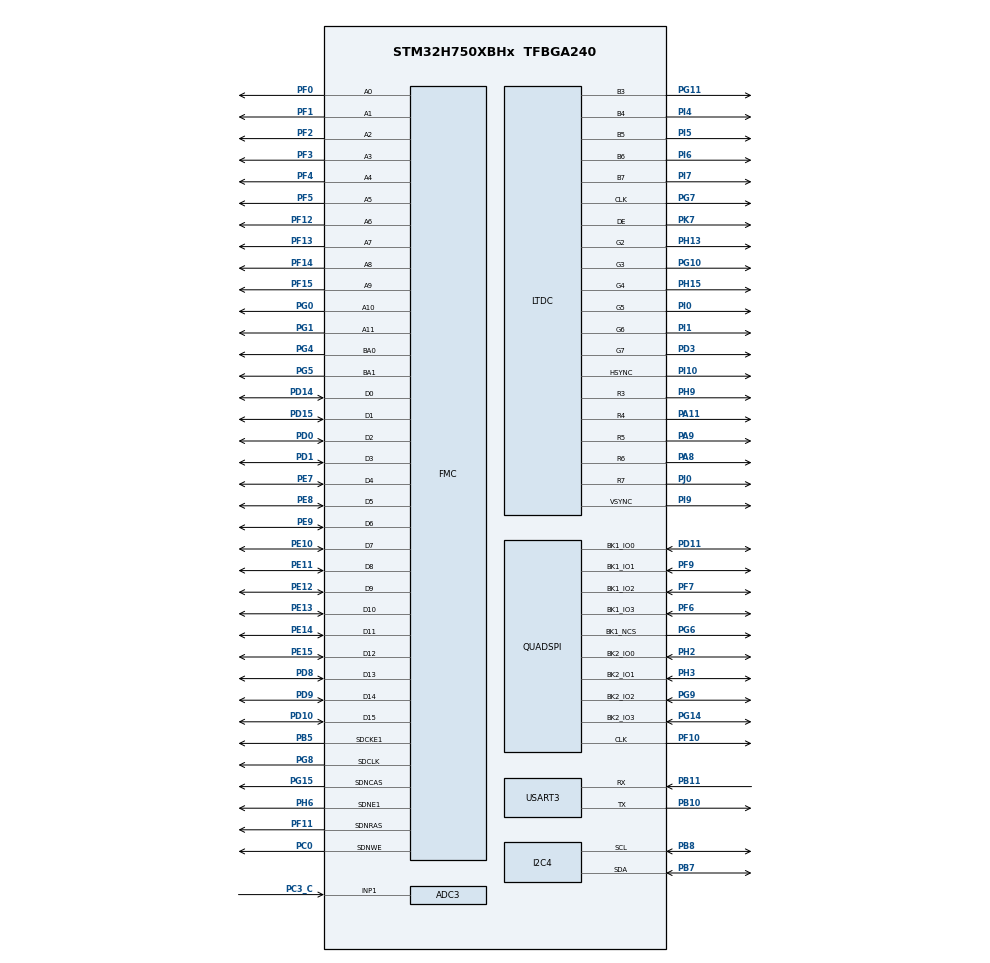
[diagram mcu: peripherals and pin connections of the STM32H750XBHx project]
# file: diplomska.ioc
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ADC3.Channel-3\#ChannelRegularConversion=ADC_CHANNEL_1
ADC3.ExternalTrigConv=ADC_EXTERNALTRIG_T2_CC2
ADC3.NbrOfConversionFlag=1
ADC3.OffsetNumber-3\#ChannelRegularConversion=ADC_OFFSET_NONE
ADC3.OffsetSignedSaturation-3\#ChannelRegularConversion=DISABLE
ADC3.Rank-3\#ChannelRegularConversion=1
ADC3.SamplingTime-3\#ChannelRegularConversion=ADC_SAMPLETIME_1CYCLE_5
CORTEX_M7.CPU_DCache=Enabled
CORTEX_M7.CPU_ICache=Enabled
CORTEX_M7.default_mode_Activation=1
DMA2D.ColorMode=DMA2D_OUTPUT_RGB565
FMC.CASLatency2=FMC_SDRAM_CAS_LATENCY_2
FMC.ExitSelfRefreshDelay2=7
FMC.LoadToActiveDelay2=2
FMC.RCDDelay2=2
FMC.RPDelay2=2
FMC.RowCycleDelay2=7
FMC.SDClockPeriod2=FMC_SDRAM_CLOCK_PERIOD_2
FMC.SelfRefreshTime2=4
FMC.WriteRecoveryTime2=3
FREERTOS.Tasks01=inferenceTask,24,3840,StartInferenceTask,Default,NULL,Dynamic,NULL,NULL;uiTask,8,2048,StartUiTask,Default,NULL,Dynamic,NULL,NULL
FREERTOS.configTOTAL_HEAP_SIZE=98304
FREERTOS.configUSE_NEWLIB_REENTRANT=1
I2C4.Timing=0x307075B1
LTDC.ActiveH=272
LTDC.ActiveW=480
Mcu.Family=STM32H7
Mcu.Name=STM32H750XBHx
Mcu.Package=TFBGA240
NVIC.DMA2D_IRQn=true\:5\:0\:false\:false\:true\:true\:true\:true\:true
NVIC.I2C4_ER_IRQn=true\:5\:0\:false\:false\:true\:true\:true\:true\:true
NVIC.I2C4_EV_IRQn=true\:5\:0\:false\:false\:true\:true\:true\:true\:true
NVIC.PriorityGroup=NVIC_PRIORITYGROUP_4
NVIC.TIM1_UP_IRQn=true\:15\:0\:false\:false\:true\:false\:false\:true\:true
NVIC.TimeBase=TIM1_UP_IRQn
NVIC.TimeBaseIP=TIM1
NVIC.USART3_IRQn=true\:5\:0\:false\:false\:true\:true\:true\:true\:true
PA11.Mode=RGB565
PA11.Signal=LTDC_R4
PA8.Mode=RGB565
PA8.Signal=LTDC_R6
PA9.Mode=RGB565
PA9.Signal=LTDC_R5
PB10.Mode=Asynchronous
PB10.Signal=USART3_TX
PB11.Mode=Asynchronous
PB11.Signal=USART3_RX
PB5.Mode=SdramChipSelect2_2
PB5.Signal=FMC_SDCKE1
PB7.Mode=I2C
PB7.Signal=I2C4_SDA
PB8.Mode=I2C
PB8.Signal=I2C4_SCL
PC0.Signal=FMC_SDNWE
PC3_C.Mode=IN1-Single-Ended
PC3_C.Signal=ADC3_INP1
PD0.Signal=FMC_D2_DA2
PD1.Signal=FMC_D3_DA3
PD10.Signal=FMC_D15_DA15
PD11.Mode=Dual_Bank
PD11.Signal=QUADSPI_BK1_IO0
PD14.Signal=FMC_D0_DA0
PD15.Signal=FMC_D1_DA1
PD3.Mode=RGB565
PD3.Signal=LTDC_G7
PD8.Signal=FMC_D13_DA13
PD9.Signal=FMC_D14_DA14
PE10.Signal=FMC_D7_DA7
PE11.Signal=FMC_D8_DA8
PE12.Signal=FMC_D9_DA9
PE13.Signal=FMC_D10_DA10
PE14.Signal=FMC_D11_DA11
PE15.Signal=FMC_D12_DA12
PE7.Signal=FMC_D4_DA4
PE8.Signal=FMC_D5_DA5
PE9.Signal=FMC_D6_DA6
PF0.Signal=FMC_A0
PF1.Signal=FMC_A1
PF10.Mode=Dual_Bank
PF10.Signal=QUADSPI_CLK
PF11.Signal=FMC_SDNRAS
PF12.Signal=FMC_A6
PF13.Signal=FMC_A7
PF14.Signal=FMC_A8
PF15.Signal=FMC_A9
PF2.Signal=FMC_A2
PF3.Signal=FMC_A3
PF4.Signal=FMC_A4
PF5.Signal=FMC_A5
PF6.Mode=Dual_Bank
PF6.Signal=QUADSPI_BK1_IO3
PF7.Mode=Dual_Bank
PF7.Signal=QUADSPI_BK1_IO2
PF9.Mode=Dual_Bank
PF9.Signal=QUADSPI_BK1_IO1
PG0.Signal=FMC_A10
PG1.Signal=FMC_A11
PG10.Mode=RGB565
PG10.Signal=LTDC_G3
PG11.Mode=RGB565
PG11.Signal=LTDC_B3
PG14.Mode=Dual_Bank
PG14.Signal=QUADSPI_BK2_IO3
PG15.Signal=FMC_SDNCAS
PG4.Signal=FMC_A14_BA0
PG5.Signal=FMC_A15_BA1
PG6.Mode=Enable Chip Select 1 for both banks
PG6.Signal=QUADSPI_BK1_NCS
PG7.Mode=RGB565
PG7.Signal=LTDC_CLK
PG8.Signal=FMC_SDCLK
PG9.Mode=Dual_Bank
PG9.Signal=QUADSPI_BK2_IO2
PH0-OSC_IN\ (PH0).Mode=HSE-External-Clock-Source
PH0-OSC_IN\ (PH0).Signal=RCC_OSC_IN
PH13.Mode=RGB565
PH13.Signal=LTDC_G2
PH15.Mode=RGB565
PH15.Signal=LTDC_G4
PH2.Mode=Dual_Bank
PH2.Signal=QUADSPI_BK2_IO0
PH3.Mode=Dual_Bank
PH3.Signal=QUADSPI_BK2_IO1
PH6.Mode=SdramChipSelect2_2
PH6.Signal=FMC_SDNE1
PH9.Mode=RGB565
PH9.Signal=LTDC_R3
PI0.Mode=RGB565
PI0.Signal=LTDC_G5
PI1.Mode=RGB565
PI1.Signal=LTDC_G6
PI10.Mode=RGB565
PI10.Signal=LTDC_HSYNC
PI4.Mode=RGB565
PI4.Signal=LTDC_B4
PI5.Mode=RGB565
PI5.Signal=LTDC_B5
PI6.Mode=RGB565
PI6.Signal=LTDC_B6
PI7.Mode=RGB565
PI7.Signal=LTDC_B7
PI9.Mode=RGB565
PI9.Signal=LTDC_VSYNC
PJ0.Mode=RGB565
PJ0.Signal=LTDC_R7
PK7.Mode=RGB565
PK7.Signal=LTDC_DE
ProjectManager.HeapSize=0x800
ProjectManager.StackSize=0x800
ProjectManager.TargetToolchain=STM32CubeIDE
QUADSPI.ChipSelectHighTime=QSPI_CS_HIGH_TIME_6_CYCLE
QUADSPI.ClockPrescaler=0
QUADSPI.FifoThreshold=4
QUADSPI.FlashSize=26
QUADSPI.SampleShifting=QSPI_SAMPLE_SHIFTING_HALFCYCLE
RCC.ADCFreq_Value=50000000
RCC.APB1CLKDivider=RCC_HCLK_DIV4
RCC.APB1Freq_Value=120000000
RCC.APB2CLKDivider=RCC_HCLK_DIV2
RCC.APB2Freq_Value=120000000
RCC.APB3Freq_Value=120000000
RCC.APB4Freq_Value=120000000
RCC.CortexFreq_Value=480000000
RCC.D1PPRE=RCC_APB3_DIV2
RCC.D2PPRE1=RCC_APB1_DIV2
RCC.D2PPRE2=RCC_APB2_DIV2
RCC.D3PPRE=RCC_APB4_DIV2
RCC.DIVM1=5
RCC.DIVM2=5
RCC.DIVM3=5
RCC.DIVN1=192
RCC.DIVN2=80
RCC.DIVN3=32
RCC.DIVP2=8
RCC.DIVQ1=4
RCC.DIVQ2=4
RCC.DIVR2=4
RCC.DIVR3=16
RCC.FLatency=FLASH_LATENCY_4
RCC.FMCCLockSelection=RCC_FMCCLKSOURCE_PLL2
RCC.HCLKFreq_Value=240000000
RCC.HPRE=RCC_HCLK_DIV2
RCC.HSE_VALUE=25000000
RCC.PLL2FRACN=0
RCC.PLL3FRACN=0
RCC.PLLFRACN=0
RCC.PLLM=25
RCC.PLLMUL=RCC_PLL_MUL9
RCC.PLLN=432
RCC.PLLQ=9
RCC.PLLSourceVirtual=RCC_PLLSOURCE_HSE
RCC.PRESCALERUSB=RCC_USBCLKSOURCE_PLL_DIV1_5
RCC.PWR_Regulator_Voltage_Scale=PWR_REGULATOR_VOLTAGE_SCALE0
RCC.QSPICLockSelection=RCC_QSPICLKSOURCE_PLL2
RCC.SYSCLKFreq_VALUE=480000000
RCC.SYSCLKSource=RCC_SYSCLKSOURCE_PLLCLK
RCC.SYSCLKSourceVirtual=RCC_SYSCLKSOURCE_PLLCLK
RCC.USBFreq_Value=240000000
SH.FMC_A0.0=FMC_A0,12b-sda2
SH.FMC_A1.0=FMC_A1,12b-sda2
SH.FMC_A10.0=FMC_A10,12b-sda2
SH.FMC_A11.0=FMC_A11,12b-sda2
SH.FMC_A14_BA0.0=FMC_BA0,FourSdramBanks2
SH.FMC_A15_BA1.0=FMC_BA1,FourSdramBanks2
SH.FMC_A2.0=FMC_A2,12b-sda2
SH.FMC_A3.0=FMC_A3,12b-sda2
SH.FMC_A4.0=FMC_A4,12b-sda2
SH.FMC_A5.0=FMC_A5,12b-sda2
SH.FMC_A6.0=FMC_A6,12b-sda2
SH.FMC_A7.0=FMC_A7,12b-sda2
SH.FMC_A8.0=FMC_A8,12b-sda2
SH.FMC_A9.0=FMC_A9,12b-sda2
SH.FMC_D0_DA0.0=FMC_D0,sd-16b-d2
SH.FMC_D10_DA10.0=FMC_D10,sd-16b-d2
SH.FMC_D11_DA11.0=FMC_D11,sd-16b-d2
SH.FMC_D12_DA12.0=FMC_D12,sd-16b-d2
SH.FMC_D13_DA13.0=FMC_D13,sd-16b-d2
SH.FMC_D14_DA14.0=FMC_D14,sd-16b-d2
SH.FMC_D15_DA15.0=FMC_D15,sd-16b-d2
SH.FMC_D1_DA1.0=FMC_D1,sd-16b-d2
SH.FMC_D2_DA2.0=FMC_D2,sd-16b-d2
SH.FMC_D3_DA3.0=FMC_D3,sd-16b-d2
SH.FMC_D4_DA4.0=FMC_D4,sd-16b-d2
SH.FMC_D5_DA5.0=FMC_D5,sd-16b-d2
SH.FMC_D6_DA6.0=FMC_D6,sd-16b-d2
SH.FMC_D7_DA7.0=FMC_D7,sd-16b-d2
SH.FMC_D8_DA8.0=FMC_D8,sd-16b-d2
SH.FMC_D9_DA9.0=FMC_D9,sd-16b-d2
SH.FMC_SDCLK.0=FMC_SDCLK,12b-sda2
SH.FMC_SDNCAS.0=FMC_SDNCAS,12b-sda2
SH.FMC_SDNRAS.0=FMC_SDNRAS,12b-sda2
SH.FMC_SDNWE.0=FMC_SDNWE,12b-sda2
STMicroelectronics.X-CUBE-AI.9.0.0.ActivationBufferSizeList=5348
STMicroelectronics.X-CUBE-AI.9.0.0.ActivationBuffers=pool0
STMicroelectronics.X-CUBE-AI.9.0.0.ActivationNames=pool0
STMicroelectronics.X-CUBE-AI.9.0.0.ActivationSizes=AI_STROKES_DATA_ACTIVATION_1_SIZE
STMicroelectronics.X-CUBE-AI.9.0.0.ApplicationCcDeviceJjApplication=ApplicationTemplate
STMicroelectronics.X-CUBE-AI.9.0.0.HeapSize=0x800
STMicroelectronics.X-CUBE-AI.9.0.0.InternalRamActivationBufferMaxSize=AI_STROKES_DATA_ACTIVATIONS_SIZE
STMicroelectronics.X-CUBE-AI.9.0.0.LatestDirectoryUsed-7118fc1bdd9c5cdb83d505c0c15efabca41f38ba9d3231cf816e6ee5fc640e7f=C\:\\Users\\cam\\Documents\\007_peskovnik\\15_delovna_mapa\\MODEL\\strokes
STMicroelectronics.X-CUBE-AI.9.0.0.LatestDirectoryUsed-9d803ac0ba18cdfca45ca4e4886879cd2de36854d513869ccf0e9e250b180b08=C\:\\Users\\cam\\Documents\\006_DIP\\003_poskus2\\jupyter
STMicroelectronics.X-CUBE-AI.9.0.0.MaximumNumberOfInputLayer=1
STMicroelectronics.X-CUBE-AI.9.0.0.MaximumNumberOfOutputLayer=1
STMicroelectronics.X-CUBE-AI.9.0.0.MaximumSizeOfInputLayer=1
STMicroelectronics.X-CUBE-AI.9.0.0.MaximumSizeOfOutputLayer=1
STMicroelectronics.X-CUBE-AI.9.0.0.ModelActualCompression-7118fc1bdd9c5cdb83d505c0c15efabca41f38ba9d3231cf816e6ee5fc640e7f=0.0
STMicroelectronics.X-CUBE-AI.9.0.0.ModelActualCompression-9d803ac0ba18cdfca45ca4e4886879cd2de36854d513869ccf0e9e250b180b08=0.0
STMicroelectronics.X-CUBE-AI.9.0.0.ModelCompression-7118fc1bdd9c5cdb83d505c0c15efabca41f38ba9d3231cf816e6ee5fc640e7f=None
STMicroelectronics.X-CUBE-AI.9.0.0.ModelCompression-9d803ac0ba18cdfca45ca4e4886879cd2de36854d513869ccf0e9e250b180b08=None
STMicroelectronics.X-CUBE-AI.9.0.0.ModelFlashOccupation-7118fc1bdd9c5cdb83d505c0c15efabca41f38ba9d3231cf816e6ee5fc640e7f=92028
STMicroelectronics.X-CUBE-AI.9.0.0.ModelFlashOccupation-9d803ac0ba18cdfca45ca4e4886879cd2de36854d513869ccf0e9e250b180b08=16104
STMicroelectronics.X-CUBE-AI.9.0.0.ModelHashList=7118fc1bdd9c5cdb83d505c0c15efabca41f38ba9d3231cf816e6ee5fc640e7f
STMicroelectronics.X-CUBE-AI.9.0.0.ModelKind-7118fc1bdd9c5cdb83d505c0c15efabca41f38ba9d3231cf816e6ee5fc640e7f=TFLITE
STMicroelectronics.X-CUBE-AI.9.0.0.ModelKind-9d803ac0ba18cdfca45ca4e4886879cd2de36854d513869ccf0e9e250b180b08=TFLITE
STMicroelectronics.X-CUBE-AI.9.0.0.ModelMacc-7118fc1bdd9c5cdb83d505c0c15efabca41f38ba9d3231cf816e6ee5fc640e7f=69872
STMicroelectronics.X-CUBE-AI.9.0.0.ModelMacc-9d803ac0ba18cdfca45ca4e4886879cd2de36854d513869ccf0e9e250b180b08=305096
STMicroelectronics.X-CUBE-AI.9.0.0.ModelName-7118fc1bdd9c5cdb83d505c0c15efabca41f38ba9d3231cf816e6ee5fc640e7f=strokes
STMicroelectronics.X-CUBE-AI.9.0.0.ModelName-9d803ac0ba18cdfca45ca4e4886879cd2de36854d513869ccf0e9e250b180b08=bitmaps
STMicroelectronics.X-CUBE-AI.9.0.0.ModelNameList=strokes
STMicroelectronics.X-CUBE-AI.9.0.0.ModelRamOccupation-7118fc1bdd9c5cdb83d505c0c15efabca41f38ba9d3231cf816e6ee5fc640e7f=5348
STMicroelectronics.X-CUBE-AI.9.0.0.ModelRamOccupation-9d803ac0ba18cdfca45ca4e4886879cd2de36854d513869ccf0e9e250b180b08=10480
STMicroelectronics.X-CUBE-AI.9.0.0.ModelStructureFile-7118fc1bdd9c5cdb83d505c0c15efabca41f38ba9d3231cf816e6ee5fc640e7f=C\:\\Users\\cam\\Documents\\007_peskovnik\\15_delovna_mapa\\MODEL\\strokes\\strokes.tflite
STMicroelectronics.X-CUBE-AI.9.0.0.ModelStructureFile-9d803ac0ba18cdfca45ca4e4886879cd2de36854d513869ccf0e9e250b180b08=C\:\\Users\\cam\\Documents\\006_DIP\\003_poskus2\\jupyter\\small-emnist.tflite
STMicroelectronics.X-CUBE-AI.9.0.0.ModelType-7118fc1bdd9c5cdb83d505c0c15efabca41f38ba9d3231cf816e6ee5fc640e7f=STM32Cube.AI MCU runtime
STMicroelectronics.X-CUBE-AI.9.0.0.ModelType-9d803ac0ba18cdfca45ca4e4886879cd2de36854d513869ccf0e9e250b180b08=STM32Cube.AI MCU runtime
STMicroelectronics.X-CUBE-AI.9.0.0.ReadyForCodeGeneration=true
STMicroelectronics.X-CUBE-AI.9.0.0.StackSize=0x800
STMicroelectronics.X-CUBE-AI.9.0.0.WorkingBufferStartAddrList=0xFFFFFFFF
STMicroelectronics.X-CUBE-AI.9.0.0.XAaCUBEAaAICcArtificialOoIntelligenceJjCore=true
STMicroelectronics.X-CUBE-AI.9.0.0.copyWeightToRam-7118fc1bdd9c5cdb83d505c0c15efabca41f38ba9d3231cf816e6ee5fc640e7f=false
STMicroelectronics.X-CUBE-AI.9.0.0.copyWeightToRam-9d803ac0ba18cdfca45ca4e4886879cd2de36854d513869ccf0e9e250b180b08=false
STMicroelectronics.X-CUBE-AI.9.0.0.customLayerConfigEnabled-7118fc1bdd9c5cdb83d505c0c15efabca41f38ba9d3231cf816e6ee5fc640e7f=false
STMicroelectronics.X-CUBE-AI.9.0.0.customLayerConfigEnabled-9d803ac0ba18cdfca45ca4e4886879cd2de36854d513869ccf0e9e250b180b08=false
STMicroelectronics.X-CUBE-AI.9.0.0.extFlashDriver-9d803ac0ba18cdfca45ca4e4886879cd2de36854d513869ccf0e9e250b180b08=Custom
STMicroelectronics.X-CUBE-AI.9.0.0.extFlashStartAddr-9d803ac0ba18cdfca45ca4e4886879cd2de36854d513869ccf0e9e250b180b08=0x90100000
STMicroelectronics.X-CUBE-AI.9.0.0.noOnnxIoTranspose-7118fc1bdd9c5cdb83d505c0c15efabca41f38ba9d3231cf816e6ee5fc640e7f=false
STMicroelectronics.X-CUBE-AI.9.0.0.noOnnxIoTranspose-9d803ac0ba18cdfca45ca4e4886879cd2de36854d513869ccf0e9e250b180b08=false
STMicroelectronics.X-CUBE-AI.9.0.0.useExternalFlash-9d803ac0ba18cdfca45ca4e4886879cd2de36854d513869ccf0e9e250b180b08=true
STMicroelectronics.X-CUBE-AI.9.0.0.useInputAllocation-7118fc1bdd9c5cdb83d505c0c15efabca41f38ba9d3231cf816e6ee5fc640e7f=true
STMicroelectronics.X-CUBE-AI.9.0.0.useInputAllocation-9d803ac0ba18cdfca45ca4e4886879cd2de36854d513869ccf0e9e250b180b08=true
STMicroelectronics.X-CUBE-AI.9.0.0.useOutputAllocation-7118fc1bdd9c5cdb83d505c0c15efabca41f38ba9d3231cf816e6ee5fc640e7f=true
STMicroelectronics.X-CUBE-AI.9.0.0.useOutputAllocation-9d803ac0ba18cdfca45ca4e4886879cd2de36854d513869ccf0e9e250b180b08=true
TIM2.Period=999
TIM2.Prescaler=23999
TIM2.TIM_MasterOutputTrigger=TIM_TRGO_UPDATE
USART3.VirtualMode-Asynchronous=VM_ASYNC
VP_DMA2D_VS_DMA2D.Mode=DMA2D_Activate
VP_FREERTOS_VS_CMSIS_V2.Mode=CMSIS_V2
VP_MEMORYMAP_VS_MEMORYMAP.Mode=CurAppReg
VP_STMicroelectronics.X-CUBE-AI_VS_ArtificialOoIntelligenceJjXAaCUBEAaAI_9.0.0.Mode=ArtificialOoIntelligenceJjXAaCUBEAaAI
VP_STMicroelectronics.X-CUBE-AI_VS_DeviceJjApplication_9.0.0.Mode=DeviceJjApplication
VP_SYS_VS_tim1.Mode=TIM1
VP_TIM2_VS_ClockSourceINT.Mode=Internal
board=custom

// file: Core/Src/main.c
/* USER CODE BEGIN Header */
/**
  ******************************************************************************
  * @file           : main.c
  * @brief          : Main program body
  ******************************************************************************
  * @attention
  *
  * Copyright (c) 2026 STMicroelectronics.
  * All rights reserved.
  *
  * This software is licensed under terms that can be found in the LICENSE file
  * in the root directory of this software component.
  * If no LICENSE file comes with this software, it is provided AS-IS.
  *
  ******************************************************************************
  */
/* USER CODE END Header */
#include "main.h"
#include "cmsis_os.h"
#include "app_x-cube-ai.h"

/* USER CODE BEGIN Includes */
#include "demo.h"
#include "stm32h750b_discovery.h"
#include "stm32h750b_discovery_qspi.h"
#include "app_msg.h"

/* USER CODE END Includes */

/* USER CODE BEGIN PD */
__attribute__((section(".framebuffer")))
uint16_t framebuffer[480 * 272];
__attribute__((section(".freertos_heap")))
uint8_t ucHeap[configTOTAL_HEAP_SIZE];
/* USER CODE END PD */

ADC_HandleTypeDef hadc3;

DMA2D_HandleTypeDef hdma2d;

I2C_HandleTypeDef hi2c4;

LTDC_HandleTypeDef hltdc;

//QSPI_HandleTypeDef hqspi;

TIM_HandleTypeDef htim2;

UART_HandleTypeDef huart3;

SDRAM_HandleTypeDef hsdram2;

/* Definitions for inferenceTask */
osThreadId_t inferenceTaskHandle;
const osThreadAttr_t inferenceTask_attributes = {
  .name = "inferenceTask",
  .stack_size = 4096 * 4,
  .priority = (osPriority_t) osPriorityNormal,
};
/* Definitions for uiTask */
osThreadId_t uiTaskHandle;
const osThreadAttr_t uiTask_attributes = {
  .name = "uiTask",
  .stack_size = 1024 * 4,
  .priority = (osPriority_t) osPriorityBelowNormal,
};
/* USER CODE BEGIN PV */
extern QSPI_HandleTypeDef hqspi;

osMessageQueueId_t logQueueHandle;
const osMessageQueueAttr_t logQueue_attributes = { .name = "logQueue" };
/* USER CODE END PV */

void SystemClock_Config(void);
void PeriphCommonClock_Config(void);
static void MPU_Config(void);
static void MX_GPIO_Init(void);
static void MX_ADC3_Init(void);
static void MX_DMA2D_Init(void);
static void MX_FMC_Init(void);
static void MX_I2C4_Init(void);
static void MX_QUADSPI_Init(void);
static void MX_USART3_UART_Init(void);
static void MX_TIM2_Init(void);
static void MX_LTDC_Local_Init(void);
void StartInferenceTask(void *argument);
void StartUiTask(void *argument);

/* USER CODE BEGIN 0 */

//void HardFault_HandlerC(uint32_t *stack)
//{
//    volatile uint32_t r0  = stack[0];
//    volatile uint32_t r1  = stack[1];
//    volatile uint32_t r2  = stack[2];
//    volatile uint32_t r3  = stack[3];
//    volatile uint32_t r12 = stack[4];
//    volatile uint32_t lr  = stack[5];
//    volatile uint32_t pc  = stack[6];
//    volatile uint32_t psr = stack[7];
//    __BKPT(0);
//}

#define SDRAM_MODEREG_BURST_LENGTH_1         0x0000
#define SDRAM_MODEREG_BURST_TYPE_SEQUENTIAL  0x0000
#define SDRAM_MODEREG_CAS_LATENCY_2          0x0020
#define SDRAM_MODEREG_WRITEBURST_MODE_SINGLE 0x0200

void SDRAM_Init(void)
{
    FMC_SDRAM_CommandTypeDef cmd = {0};
    uint32_t tmpr = 0;

    cmd.CommandMode           = FMC_SDRAM_CMD_CLK_ENABLE;
    cmd.CommandTarget         = FMC_SDRAM_CMD_TARGET_BANK2;
    cmd.AutoRefreshNumber     = 1;
    cmd.ModeRegisterDefinition = 0;
    HAL_SDRAM_SendCommand(&hsdram2, &cmd, 0xFFFF);
    HAL_Delay(1);

    cmd.CommandMode = FMC_SDRAM_CMD_PALL;
    HAL_SDRAM_SendCommand(&hsdram2, &cmd, 0xFFFF);

    cmd.CommandMode       = FMC_SDRAM_CMD_AUTOREFRESH_MODE;
    cmd.AutoRefreshNumber = 8;
    HAL_SDRAM_SendCommand(&hsdram2, &cmd, 0xFFFF);

    tmpr = SDRAM_MODEREG_BURST_LENGTH_1        |
           SDRAM_MODEREG_BURST_TYPE_SEQUENTIAL  |
           SDRAM_MODEREG_CAS_LATENCY_2          |
           SDRAM_MODEREG_WRITEBURST_MODE_SINGLE;

    cmd.CommandMode            = FMC_SDRAM_CMD_LOAD_MODE;
    cmd.AutoRefreshNumber      = 1;
    cmd.ModeRegisterDefinition = tmpr;
    HAL_SDRAM_SendCommand(&hsdram2, &cmd, 0xFFFF);

    HAL_SDRAM_ProgramRefreshRate(&hsdram2, 1754);
}

/* USER CODE END 0 */

int main(void)
{

  /* MPU Configuration--------------------------------------------------------*/
  MPU_Config();

  /* Enable the CPU Cache */

  /* Enable I-Cache---------------------------------------------------------*/
  SCB_EnableICache();

  /* Enable D-Cache---------------------------------------------------------*/
  SCB_EnableDCache();

  /* MCU Configuration--------------------------------------------------------*/

  /* Reset of all peripherals, Initializes the Flash interface and the Systick. */
  HAL_Init();

  /* Configure the system clock */
  SystemClock_Config();

  /* Configure the peripherals common clocks */
  PeriphCommonClock_Config();

  /* Initialize all configured peripherals */
//  MX_GPIO_Init();
//  MX_ADC3_Init();
//  MX_DMA2D_Init();
//  MX_FMC_Init();
//  MX_I2C4_Init();
//  MX_QUADSPI_Init();
//  MX_USART3_UART_Init();
//  MX_TIM2_Init();
//  MX_LTDC_Local_Init();
//  MX_X_CUBE_AI_Init();
  /* USER CODE BEGIN 2 */

  MX_GPIO_Init();
  MX_FMC_Init();
  SDRAM_Init();

  MX_ADC3_Init();
  MX_DMA2D_Init();
  MX_I2C4_Init();

  MX_QUADSPI_Init();

  BSP_QSPI_Init_t qspi_cfg;
  qspi_cfg.InterfaceMode = MT25TL01G_QPI_MODE;
  qspi_cfg.TransferRate  = MT25TL01G_DTR_TRANSFER;
  qspi_cfg.DualFlashMode = MT25TL01G_DUALFLASH_ENABLE;

  if (BSP_QSPI_Init(0, &qspi_cfg) != BSP_ERROR_NONE) {
	  __BKPT(0);
  }
  if (BSP_QSPI_EnableMemoryMappedMode(0) != BSP_ERROR_NONE) {
    __BKPT(1);
  }

//  uint8_t test_val = *(volatile uint8_t*)0x90100000;
//
//  volatile uint64_t *qspi = (uint32_t *)0x90000000;
//
//  uint64_t first_word = *qspi;
//  volatile uint64_t b0 = qspi[0];
//  volatile uint64_t b1 = qspi[1];
//  volatile uint64_t b2 = qspi[2];
//  volatile uint64_t b3 = qspi[3];
//  volatile uint64_t b4 = qspi[4];
//  volatile uint64_t b5 = qspi[5];
//  volatile uint64_t b6 = qspi[6];
//  volatile uint64_t b7 = qspi[7];

  MX_USART3_UART_Init();
  MX_LTDC_Local_Init();
  MX_TIM2_Init();
  MX_X_CUBE_AI_Init();

  CoreDebug->DEMCR |= CoreDebug_DEMCR_TRCENA_Msk;
  DWT->LAR = 0xC5ACCE55;
  DWT->CYCCNT = 0;
  DWT->CTRL |= DWT_CTRL_CYCCNTENA_Msk;

  /* USER CODE END 2 */

  /* Init scheduler */
  osKernelInitialize();

  /* USER CODE BEGIN RTOS_QUEUES */
  /* add queues, ... */
  logQueueHandle = osMessageQueueNew(64, sizeof(log_msg_t), &logQueue_attributes);
  /* USER CODE END RTOS_QUEUES */

  /* Create the thread(s) */
  /* creation of inferenceTask */
  inferenceTaskHandle = osThreadNew(StartInferenceTask, NULL, &inferenceTask_attributes);

  /* creation of uiTask */
  uiTaskHandle = osThreadNew(StartUiTask, NULL, &uiTask_attributes);

  /* Start scheduler */
  osKernelStart();

  /* We should never get here as control is now taken by the scheduler */

  /* Infinite loop */
  while (1)
  {

  }
}

void SystemClock_Config(void)
{
  RCC_OscInitTypeDef RCC_OscInitStruct = {0};
  RCC_ClkInitTypeDef RCC_ClkInitStruct = {0};

  /** Supply configuration update enable
  */
  HAL_PWREx_ConfigSupply(PWR_LDO_SUPPLY);

  /** Configure the main internal regulator output voltage
  */
  __HAL_PWR_VOLTAGESCALING_CONFIG(PWR_REGULATOR_VOLTAGE_SCALE1);

  while(!__HAL_PWR_GET_FLAG(PWR_FLAG_VOSRDY)) {}

  __HAL_RCC_SYSCFG_CLK_ENABLE();
  __HAL_PWR_VOLTAGESCALING_CONFIG(PWR_REGULATOR_VOLTAGE_SCALE0);

  while(!__HAL_PWR_GET_FLAG(PWR_FLAG_VOSRDY)) {}

  /** Initializes the RCC Oscillators according to the specified parameters
  * in the RCC_OscInitTypeDef structure.
  */
  RCC_OscInitStruct.OscillatorType = RCC_OSCILLATORTYPE_HSE;
  RCC_OscInitStruct.HSEState = RCC_HSE_BYPASS;
  RCC_OscInitStruct.PLL.PLLState = RCC_PLL_ON;
  RCC_OscInitStruct.PLL.PLLSource = RCC_PLLSOURCE_HSE;
  RCC_OscInitStruct.PLL.PLLM = 5;
  RCC_OscInitStruct.PLL.PLLN = 192;
  RCC_OscInitStruct.PLL.PLLP = 2;
  RCC_OscInitStruct.PLL.PLLQ = 4;
  RCC_OscInitStruct.PLL.PLLR = 2;
  RCC_OscInitStruct.PLL.PLLRGE = RCC_PLL1VCIRANGE_2;
  RCC_OscInitStruct.PLL.PLLVCOSEL = RCC_PLL1VCOWIDE;
  RCC_OscInitStruct.PLL.PLLFRACN = 0;
  if (HAL_RCC_OscConfig(&RCC_OscInitStruct) != HAL_OK)
  {
    Error_Handler();
  }

  /** Initializes the CPU, AHB and APB buses clocks
  */
  RCC_ClkInitStruct.ClockType = RCC_CLOCKTYPE_HCLK|RCC_CLOCKTYPE_SYSCLK
                              |RCC_CLOCKTYPE_PCLK1|RCC_CLOCKTYPE_PCLK2
                              |RCC_CLOCKTYPE_D3PCLK1|RCC_CLOCKTYPE_D1PCLK1;
  RCC_ClkInitStruct.SYSCLKSource = RCC_SYSCLKSOURCE_PLLCLK;
  RCC_ClkInitStruct.SYSCLKDivider = RCC_SYSCLK_DIV1;
  RCC_ClkInitStruct.AHBCLKDivider = RCC_HCLK_DIV2;
  RCC_ClkInitStruct.APB3CLKDivider = RCC_APB3_DIV2;
  RCC_ClkInitStruct.APB1CLKDivider = RCC_APB1_DIV2;
  RCC_ClkInitStruct.APB2CLKDivider = RCC_APB2_DIV2;
  RCC_ClkInitStruct.APB4CLKDivider = RCC_APB4_DIV2;

  if (HAL_RCC_ClockConfig(&RCC_ClkInitStruct, FLASH_LATENCY_4) != HAL_OK)
  {
    Error_Handler();
  }
}

void PeriphCommonClock_Config(void)
{
  RCC_PeriphCLKInitTypeDef PeriphClkInitStruct = {0};

  /** Initializes the peripherals clock
  */
  PeriphClkInitStruct.PeriphClockSelection = RCC_PERIPHCLK_FMC|RCC_PERIPHCLK_QSPI
                              |RCC_PERIPHCLK_ADC;
  PeriphClkInitStruct.PLL2.PLL2M = 5;
  PeriphClkInitStruct.PLL2.PLL2N = 80;
  PeriphClkInitStruct.PLL2.PLL2P = 8;
  PeriphClkInitStruct.PLL2.PLL2Q = 4;
  PeriphClkInitStruct.PLL2.PLL2R = 4;
  PeriphClkInitStruct.PLL2.PLL2RGE = RCC_PLL2VCIRANGE_2;
  PeriphClkInitStruct.PLL2.PLL2VCOSEL = RCC_PLL2VCOWIDE;
  PeriphClkInitStruct.PLL2.PLL2FRACN = 0;
  PeriphClkInitStruct.FmcClockSelection = RCC_FMCCLKSOURCE_PLL2;
  PeriphClkInitStruct.QspiClockSelection = RCC_QSPICLKSOURCE_PLL2;
  PeriphClkInitStruct.AdcClockSelection = RCC_ADCCLKSOURCE_PLL2;
  if (HAL_RCCEx_PeriphCLKConfig(&PeriphClkInitStruct) != HAL_OK)
  {
    Error_Handler();
  }
}

static void MX_ADC3_Init(void)
{

  ADC_ChannelConfTypeDef sConfig = {0};

  /** Common config
  */
  hadc3.Instance = ADC3;
  hadc3.Init.ClockPrescaler = ADC_CLOCK_ASYNC_DIV1;
  hadc3.Init.ScanConvMode = ADC_SCAN_DISABLE;
  hadc3.Init.EOCSelection = ADC_EOC_SINGLE_CONV;
  hadc3.Init.LowPowerAutoWait = DISABLE;
  hadc3.Init.ContinuousConvMode = DISABLE;
  hadc3.Init.NbrOfConversion = 1;
  hadc3.Init.DiscontinuousConvMode = DISABLE;
  hadc3.Init.ExternalTrigConv = ADC_EXTERNALTRIG_T2_CC2;
  hadc3.Init.ExternalTrigConvEdge = ADC_EXTERNALTRIGCONVEDGE_RISING;
  hadc3.Init.ConversionDataManagement = ADC_CONVERSIONDATA_DR;
  hadc3.Init.Overrun = ADC_OVR_DATA_PRESERVED;
  hadc3.Init.LeftBitShift = ADC_LEFTBITSHIFT_NONE;
  hadc3.Init.OversamplingMode = DISABLE;
  hadc3.Init.Oversampling.Ratio = 1;
  if (HAL_ADC_Init(&hadc3) != HAL_OK)
  {
    Error_Handler();
  }
  hadc3.Init.Resolution = ADC_RESOLUTION_16B;
  if (HAL_ADC_Init(&hadc3) != HAL_OK)
  {
    Error_Handler();
  }

  /** Configure Regular Channel
  */
  sConfig.Channel = ADC_CHANNEL_1;
  sConfig.Rank = ADC_REGULAR_RANK_1;
  sConfig.SamplingTime = ADC_SAMPLETIME_1CYCLE_5;
  sConfig.SingleDiff = ADC_SINGLE_ENDED;
  sConfig.OffsetNumber = ADC_OFFSET_NONE;
  sConfig.Offset = 0;
  sConfig.OffsetSignedSaturation = DISABLE;
  if (HAL_ADC_ConfigChannel(&hadc3, &sConfig) != HAL_OK)
  {
    Error_Handler();
  }

}

static void MX_DMA2D_Init(void)
{

  hdma2d.Instance = DMA2D;
  hdma2d.Init.Mode = DMA2D_M2M;
  hdma2d.Init.ColorMode = DMA2D_OUTPUT_RGB565;
  hdma2d.Init.OutputOffset = 0;
  hdma2d.LayerCfg[1].InputOffset = 0;
  hdma2d.LayerCfg[1].InputColorMode = DMA2D_INPUT_RGB565;
  hdma2d.LayerCfg[1].AlphaMode = DMA2D_NO_MODIF_ALPHA;
  hdma2d.LayerCfg[1].InputAlpha = 0;
  hdma2d.LayerCfg[1].AlphaInverted = DMA2D_REGULAR_ALPHA;
  hdma2d.LayerCfg[1].RedBlueSwap = DMA2D_RB_REGULAR;
  hdma2d.LayerCfg[1].ChromaSubSampling = DMA2D_NO_CSS;
  if (HAL_DMA2D_Init(&hdma2d) != HAL_OK)
  {
    Error_Handler();
  }
  if (HAL_DMA2D_ConfigLayer(&hdma2d, 1) != HAL_OK)
  {
    Error_Handler();
  }

}

static void MX_I2C4_Init(void)
{

  hi2c4.Instance = I2C4;
  hi2c4.Init.Timing = 0x307075B1;
  hi2c4.Init.OwnAddress1 = 0;
  hi2c4.Init.AddressingMode = I2C_ADDRESSINGMODE_7BIT;
  hi2c4.Init.DualAddressMode = I2C_DUALADDRESS_DISABLE;
  hi2c4.Init.OwnAddress2 = 0;
  hi2c4.Init.OwnAddress2Masks = I2C_OA2_NOMASK;
  hi2c4.Init.GeneralCallMode = I2C_GENERALCALL_DISABLE;
  hi2c4.Init.NoStretchMode = I2C_NOSTRETCH_DISABLE;
  if (HAL_I2C_Init(&hi2c4) != HAL_OK)
  {
    Error_Handler();
  }

  /** Configure Analogue filter
  */
  if (HAL_I2CEx_ConfigAnalogFilter(&hi2c4, I2C_ANALOGFILTER_ENABLE) != HAL_OK)
  {
    Error_Handler();
  }

  /** Configure Digital filter
  */
  if (HAL_I2CEx_ConfigDigitalFilter(&hi2c4, 0) != HAL_OK)
  {
    Error_Handler();
  }

}

static void MX_LTDC_Local_Init(void)
{

  LTDC_LayerCfgTypeDef pLayerCfg = {0};
  LTDC_LayerCfgTypeDef pLayerCfg1 = {0};

  hltdc.Instance = LTDC;
  hltdc.Init.HSPolarity = LTDC_HSPOLARITY_AL;
  hltdc.Init.VSPolarity = LTDC_VSPOLARITY_AL;
  hltdc.Init.DEPolarity = LTDC_DEPOLARITY_AL;
  hltdc.Init.PCPolarity = LTDC_PCPOLARITY_IPC;
  hltdc.Init.HorizontalSync = 7;
  hltdc.Init.VerticalSync = 3;
  hltdc.Init.AccumulatedHBP = 14;
  hltdc.Init.AccumulatedVBP = 5;
  hltdc.Init.AccumulatedActiveW = 494;
  hltdc.Init.AccumulatedActiveH = 277;
  hltdc.Init.TotalWidth = 500;
  hltdc.Init.TotalHeigh = 279;
  hltdc.Init.Backcolor.Blue = 0;
  hltdc.Init.Backcolor.Green = 0;
  hltdc.Init.Backcolor.Red = 0;
  if (HAL_LTDC_Init(&hltdc) != HAL_OK)
  {
    Error_Handler();
  }
  pLayerCfg.WindowX0 = 0;
  pLayerCfg.WindowX1 = 0;
  pLayerCfg.WindowY0 = 0;
  pLayerCfg.WindowY1 = 0;
  pLayerCfg.PixelFormat = LTDC_PIXEL_FORMAT_ARGB8888;
  pLayerCfg.Alpha = 0;
  pLayerCfg.Alpha0 = 0;
  pLayerCfg.BlendingFactor1 = LTDC_BLENDING_FACTOR1_CA;
  pLayerCfg.BlendingFactor2 = LTDC_BLENDING_FACTOR2_CA;
  pLayerCfg.FBStartAdress = 0;
  pLayerCfg.ImageWidth = 0;
  pLayerCfg.ImageHeight = 0;
  pLayerCfg.Backcolor.Blue = 0;
  pLayerCfg.Backcolor.Green = 0;
  pLayerCfg.Backcolor.Red = 0;
  if (HAL_LTDC_ConfigLayer(&hltdc, &pLayerCfg, 0) != HAL_OK)
  {
    Error_Handler();
  }
  pLayerCfg1.WindowX0 = 0;
  pLayerCfg1.WindowX1 = 0;
  pLayerCfg1.WindowY0 = 0;
  pLayerCfg1.WindowY1 = 0;
  pLayerCfg1.PixelFormat = LTDC_PIXEL_FORMAT_ARGB8888;
  pLayerCfg1.Alpha = 0;
  pLayerCfg1.Alpha0 = 0;
  pLayerCfg1.BlendingFactor1 = LTDC_BLENDING_FACTOR1_CA;
  pLayerCfg1.BlendingFactor2 = LTDC_BLENDING_FACTOR2_CA;
  pLayerCfg1.FBStartAdress = 0;
  pLayerCfg1.ImageWidth = 0;
  pLayerCfg1.ImageHeight = 0;
  pLayerCfg1.Backcolor.Blue = 0;
  pLayerCfg1.Backcolor.Green = 0;
  pLayerCfg1.Backcolor.Red = 0;
  if (HAL_LTDC_ConfigLayer(&hltdc, &pLayerCfg1, 1) != HAL_OK)
  {
    Error_Handler();
  }

}

static void MX_QUADSPI_Init(void)
{

  /* QUADSPI parameter configuration*/
  hqspi.Instance = QUADSPI;
  hqspi.Init.ClockPrescaler = 0;
  hqspi.Init.FifoThreshold = 4;
  hqspi.Init.SampleShifting = QSPI_SAMPLE_SHIFTING_HALFCYCLE;
  hqspi.Init.FlashSize = 26;
  hqspi.Init.ChipSelectHighTime = QSPI_CS_HIGH_TIME_6_CYCLE;
  hqspi.Init.ClockMode = QSPI_CLOCK_MODE_0;
  hqspi.Init.DualFlash = QSPI_DUALFLASH_ENABLE;
  if (HAL_QSPI_Init(&hqspi) != HAL_OK)
  {
    Error_Handler();
  }

}

static void MX_TIM2_Init(void)
{

  TIM_ClockConfigTypeDef sClockSourceConfig = {0};
  TIM_MasterConfigTypeDef sMasterConfig = {0};

  htim2.Instance = TIM2;
  htim2.Init.Prescaler = 23999;
  htim2.Init.CounterMode = TIM_COUNTERMODE_UP;
  htim2.Init.Period = 999;
  htim2.Init.ClockDivision = TIM_CLOCKDIVISION_DIV1;
  htim2.Init.AutoReloadPreload = TIM_AUTORELOAD_PRELOAD_DISABLE;
  if (HAL_TIM_Base_Init(&htim2) != HAL_OK)
  {
    Error_Handler();
  }
  sClockSourceConfig.ClockSource = TIM_CLOCKSOURCE_INTERNAL;
  if (HAL_TIM_ConfigClockSource(&htim2, &sClockSourceConfig) != HAL_OK)
  {
    Error_Handler();
  }
  sMasterConfig.MasterOutputTrigger = TIM_TRGO_UPDATE;
  sMasterConfig.MasterSlaveMode = TIM_MASTERSLAVEMODE_DISABLE;
  if (HAL_TIMEx_MasterConfigSynchronization(&htim2, &sMasterConfig) != HAL_OK)
  {
    Error_Handler();
  }

}

static void MX_USART3_UART_Init(void)
{

  huart3.Instance = USART3;
  huart3.Init.BaudRate = 115200;
  huart3.Init.WordLength = UART_WORDLENGTH_8B;
  huart3.Init.StopBits = UART_STOPBITS_1;
  huart3.Init.Parity = UART_PARITY_NONE;
  huart3.Init.Mode = UART_MODE_TX_RX;
  huart3.Init.HwFlowCtl = UART_HWCONTROL_NONE;
  huart3.Init.OverSampling = UART_OVERSAMPLING_16;
  huart3.Init.OneBitSampling = UART_ONE_BIT_SAMPLE_DISABLE;
  huart3.Init.ClockPrescaler = UART_PRESCALER_DIV1;
  huart3.AdvancedInit.AdvFeatureInit = UART_ADVFEATURE_NO_INIT;
  if (HAL_UART_Init(&huart3) != HAL_OK)
  {
    Error_Handler();
  }
  if (HAL_UARTEx_SetTxFifoThreshold(&huart3, UART_TXFIFO_THRESHOLD_1_8) != HAL_OK)
  {
    Error_Handler();
  }
  if (HAL_UARTEx_SetRxFifoThreshold(&huart3, UART_RXFIFO_THRESHOLD_1_8) != HAL_OK)
  {
    Error_Handler();
  }
  if (HAL_UARTEx_DisableFifoMode(&huart3) != HAL_OK)
  {
    Error_Handler();
  }

}

/* FMC initialization function */
static void MX_FMC_Init(void)
{

  FMC_SDRAM_TimingTypeDef SdramTiming = {0};

  /** Perform the SDRAM2 memory initialization sequence
  */
  hsdram2.Instance = FMC_SDRAM_DEVICE;
  /* hsdram2.Init */
  hsdram2.Init.SDBank = FMC_SDRAM_BANK2;
  hsdram2.Init.ColumnBitsNumber = FMC_SDRAM_COLUMN_BITS_NUM_8;
  hsdram2.Init.RowBitsNumber = FMC_SDRAM_ROW_BITS_NUM_12;
  hsdram2.Init.MemoryDataWidth = FMC_SDRAM_MEM_BUS_WIDTH_16;
  hsdram2.Init.InternalBankNumber = FMC_SDRAM_INTERN_BANKS_NUM_4;
  hsdram2.Init.CASLatency = FMC_SDRAM_CAS_LATENCY_2;
  hsdram2.Init.WriteProtection = FMC_SDRAM_WRITE_PROTECTION_DISABLE;
  hsdram2.Init.SDClockPeriod = FMC_SDRAM_CLOCK_PERIOD_2;
  hsdram2.Init.ReadBurst = FMC_SDRAM_RBURST_DISABLE;
  hsdram2.Init.ReadPipeDelay = FMC_SDRAM_RPIPE_DELAY_0;
  /* SdramTiming */
  SdramTiming.LoadToActiveDelay = 2;
  SdramTiming.ExitSelfRefreshDelay = 7;
  SdramTiming.SelfRefreshTime = 4;
  SdramTiming.RowCycleDelay = 7;
  SdramTiming.WriteRecoveryTime = 3;
  SdramTiming.RPDelay = 2;
  SdramTiming.RCDDelay = 2;

  if (HAL_SDRAM_Init(&hsdram2, &SdramTiming) != HAL_OK)
  {
    Error_Handler( );
  }

}

static void MX_GPIO_Init(void)
{

  /* GPIO Ports Clock Enable */
  __HAL_RCC_GPIOI_CLK_ENABLE();
  __HAL_RCC_GPIOB_CLK_ENABLE();
  __HAL_RCC_GPIOG_CLK_ENABLE();
  __HAL_RCC_GPIOD_CLK_ENABLE();
  __HAL_RCC_GPIOH_CLK_ENABLE();
  __HAL_RCC_GPIOK_CLK_ENABLE();
  __HAL_RCC_GPIOA_CLK_ENABLE();
  __HAL_RCC_GPIOF_CLK_ENABLE();
  __HAL_RCC_GPIOC_CLK_ENABLE();
  __HAL_RCC_GPIOJ_CLK_ENABLE();
  __HAL_RCC_GPIOE_CLK_ENABLE();

}

void StartInferenceTask(void *argument)
{
  /* USER CODE BEGIN 5 */
	letter_demo_init();
  /* Infinite loop */
  for(;;)
  {
	  //letter_demo();
	  letter_demo_run_once();
	  osDelay(5000);
  }
  /* USER CODE END 5 */
}

void StartUiTask(void *argument)
{
  /* USER CODE BEGIN StartUiTask */

	log_msg_t msg;
  /* Infinite loop */
  for(;;)
  {
      if (osMessageQueueGet(logQueueHandle, &msg, NULL, osWaitForever) == osOK) {
          logger_print(&msg);   // implementirano v demo.c ali ločenem logger.c
      }
  }
  /* USER CODE END StartUiTask */
}

 /* MPU Configuration */

void MPU_Config(void)
{
  MPU_Region_InitTypeDef MPU_InitStruct = {0};
  HAL_MPU_Disable();

  MPU_InitStruct.Enable = MPU_REGION_ENABLE;
  MPU_InitStruct.Number = MPU_REGION_NUMBER0;
  MPU_InitStruct.BaseAddress = 0x0;
  MPU_InitStruct.Size = MPU_REGION_SIZE_4GB;
  MPU_InitStruct.SubRegionDisable = 0x87;
  MPU_InitStruct.TypeExtField = MPU_TEX_LEVEL0;
  MPU_InitStruct.AccessPermission = MPU_REGION_NO_ACCESS;
  MPU_InitStruct.DisableExec = MPU_INSTRUCTION_ACCESS_DISABLE;
  MPU_InitStruct.IsShareable = MPU_ACCESS_SHAREABLE;
  MPU_InitStruct.IsCacheable = MPU_ACCESS_NOT_CACHEABLE;
  MPU_InitStruct.IsBufferable = MPU_ACCESS_NOT_BUFFERABLE;
  HAL_MPU_ConfigRegion(&MPU_InitStruct);

  /*QSPI uteži */
  MPU_InitStruct.Enable = MPU_REGION_ENABLE;
  MPU_InitStruct.Number = MPU_REGION_NUMBER1;
  MPU_InitStruct.BaseAddress = 0x90000000;
  MPU_InitStruct.Size = MPU_REGION_SIZE_128MB;
  MPU_InitStruct.SubRegionDisable = 0x0;
  MPU_InitStruct.TypeExtField = MPU_TEX_LEVEL0;
  MPU_InitStruct.AccessPermission = MPU_REGION_FULL_ACCESS;
  MPU_InitStruct.DisableExec = MPU_INSTRUCTION_ACCESS_ENABLE;
  MPU_InitStruct.IsShareable = MPU_ACCESS_NOT_SHAREABLE;
  MPU_InitStruct.IsCacheable = MPU_ACCESS_NOT_CACHEABLE;
  MPU_InitStruct.IsBufferable = MPU_ACCESS_NOT_BUFFERABLE;
  HAL_MPU_ConfigRegion(&MPU_InitStruct);

  /*SDRAM*/
  MPU_InitStruct.Enable           = MPU_REGION_ENABLE;
  MPU_InitStruct.Number           = MPU_REGION_NUMBER2;
  MPU_InitStruct.BaseAddress      = 0xD0000000;
  MPU_InitStruct.Size             = MPU_REGION_SIZE_32MB;
  MPU_InitStruct.SubRegionDisable = 0x00;
  MPU_InitStruct.TypeExtField     = MPU_TEX_LEVEL0;
  MPU_InitStruct.AccessPermission = MPU_REGION_FULL_ACCESS;
  MPU_InitStruct.DisableExec      = MPU_INSTRUCTION_ACCESS_DISABLE;
  MPU_InitStruct.IsShareable      = MPU_ACCESS_NOT_SHAREABLE;
  MPU_InitStruct.IsCacheable      = MPU_ACCESS_CACHEABLE;
  MPU_InitStruct.IsBufferable     = MPU_ACCESS_BUFFERABLE;
  HAL_MPU_ConfigRegion(&MPU_InitStruct);

  HAL_MPU_Enable(MPU_PRIVILEGED_DEFAULT);
}

void HAL_TIM_PeriodElapsedCallback(TIM_HandleTypeDef *htim)
{
  if (htim->Instance == TIM1) {
    HAL_IncTick();
  }
}

void Error_Handler(void)
{
  __disable_irq();
  while (1)
  {
  }
}
